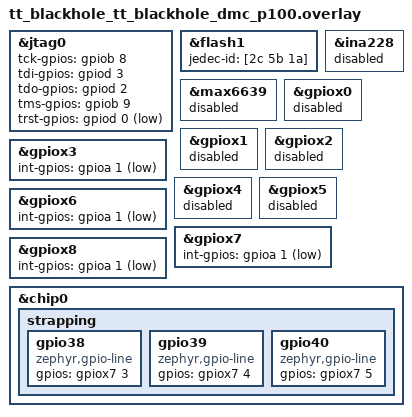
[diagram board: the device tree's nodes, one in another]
/*
 * Copyright (c) 2024 Tenstorrent AI ULC
 *
 * SPDX-License-Identifier: Apache-2.0
 */

&jtag0 {
	tck-gpios = <&gpiob 8 GPIO_ACTIVE_HIGH>;
	tdi-gpios = <&gpiod 3 GPIO_ACTIVE_HIGH>;
	tdo-gpios = <&gpiod 2 GPIO_ACTIVE_HIGH>;
	tms-gpios = <&gpiob 9 GPIO_ACTIVE_HIGH>;
	trst-gpios = <&gpiod 0 GPIO_ACTIVE_LOW>;
};

&flash1 {
	jedec-id = [2c 5b 1a];
};

&ina228 {
	status = "disabled";
};

&max6639 {
	status = "disabled";
};

&gpiox0 {
	status = "disabled";
};

&gpiox1 {
	status = "disabled";
};

&gpiox2 {
	status = "disabled";
};

&gpiox3 {
	status = "okay";
	int-gpios = <&gpioa 1 GPIO_ACTIVE_LOW>;
};

&gpiox4 {
	status = "disabled";
};

&gpiox5 {
	status = "disabled";
};

&gpiox6 {
	status = "okay";
	int-gpios = <&gpioa 1 GPIO_ACTIVE_LOW>;
};

&gpiox7 {
	status = "okay";
	int-gpios = <&gpioa 1 GPIO_ACTIVE_LOW>;
};

&gpiox8 {
	status = "okay";
	int-gpios = <&gpioa 1 GPIO_ACTIVE_LOW>;
};

&chip0 {
	/* Use OCTAL DDR SPI mode, GPIO[39:38] = 3 is OCTAL mode, GPIO40 is DDR_EN */
	strapping {
		/* GPIO pin representing strap GPIO38_SPI_MODE_0 */
		gpio38 {
			compatible = "zephyr,gpio-line";
			gpios = <&gpiox7 3 GPIO_ACTIVE_HIGH>;
		};

		/* GPIO pin representing strap GPIO39_SPI_MODE_1 */
		gpio39 {
			compatible = "zephyr,gpio-line";
			gpios = <&gpiox7 4 GPIO_ACTIVE_HIGH>;
		};

		/* GPIO pin representing strap GPIO40_SPI_DDR_EN */
		gpio40 {
			compatible = "zephyr,gpio-line";
			gpios = <&gpiox7 5 GPIO_ACTIVE_HIGH>;
		};
	};
};
